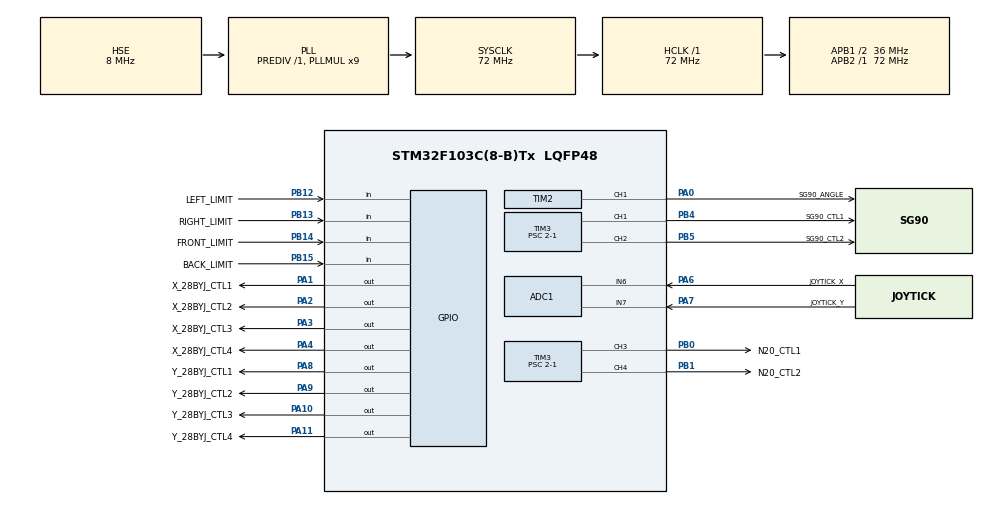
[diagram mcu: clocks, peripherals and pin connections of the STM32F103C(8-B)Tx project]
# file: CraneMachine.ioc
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ADC1.Channel-0\#ChannelRegularConversion=ADC_CHANNEL_6
ADC1.NbrOfConversionFlag=1
ADC1.Rank-0\#ChannelRegularConversion=1
ADC1.SamplingTime-0\#ChannelRegularConversion=ADC_SAMPLETIME_1CYCLE_5
ADC1.master=1
Mcu.Family=STM32F1
Mcu.Name=STM32F103C(8-B)Tx
Mcu.Package=LQFP48
NVIC.PriorityGroup=NVIC_PRIORITYGROUP_4
NVIC.TIM1_UP_IRQn=true\:0\:0\:false\:false\:true\:true\:true\:true
NVIC.TIM4_IRQn=true\:0\:0\:false\:false\:true\:true\:true\:true
PA0-WKUP.GPIO_Label=SG90_ANGLE
PA0-WKUP.GPIO_Speed=GPIO_SPEED_FREQ_HIGH
PA0-WKUP.Signal=S_TIM2_CH1_ETR
PA1.GPIO_Label=X_28BYJ_CTL1
PA1.GPIO_Speed=GPIO_SPEED_FREQ_HIGH
PA1.Signal=GPIO_Output
PA10.GPIO_Label=Y_28BYJ_CTL3
PA10.GPIO_Speed=GPIO_SPEED_FREQ_HIGH
PA10.Signal=GPIO_Output
PA11.GPIO_Label=Y_28BYJ_CTL4
PA11.GPIO_Speed=GPIO_SPEED_FREQ_HIGH
PA11.Signal=GPIO_Output
PA13.Mode=Serial_Wire
PA13.Signal=SYS_JTMS-SWDIO
PA14.Mode=Serial_Wire
PA14.Signal=SYS_JTCK-SWCLK
PA2.GPIO_Label=X_28BYJ_CTL2
PA2.GPIO_Speed=GPIO_SPEED_FREQ_HIGH
PA2.Signal=GPIO_Output
PA3.GPIO_Label=X_28BYJ_CTL3
PA3.GPIO_Speed=GPIO_SPEED_FREQ_HIGH
PA3.Signal=GPIO_Output
PA4.GPIO_Label=X_28BYJ_CTL4
PA4.GPIO_Speed=GPIO_SPEED_FREQ_HIGH
PA4.Signal=GPIO_Output
PA6.GPIO_Label=JOYTICK_X
PA6.Signal=ADCx_IN6
PA7.GPIO_Label=JOYTICK_Y
PA7.Signal=ADCx_IN7
PA8.GPIO_Label=Y_28BYJ_CTL1
PA8.GPIO_Speed=GPIO_SPEED_FREQ_HIGH
PA8.Signal=GPIO_Output
PA9.GPIO_Label=Y_28BYJ_CTL2
PA9.GPIO_Speed=GPIO_SPEED_FREQ_HIGH
PA9.Signal=GPIO_Output
PB0.GPIO_Label=N20_CTL1
PB0.GPIO_Speed=GPIO_SPEED_FREQ_HIGH
PB0.Signal=S_TIM3_CH3
PB1.GPIO_Label=N20_CTL2
PB1.Signal=S_TIM3_CH4
PB12.GPIO_Label=LEFT_LIMIT
PB12.GPIO_PuPd=GPIO_PULLUP
PB12.Signal=GPIO_Input
PB13.GPIO_Label=RIGHT_LIMIT
PB13.GPIO_PuPd=GPIO_PULLUP
PB13.Signal=GPIO_Input
PB14.GPIO_Label=FRONT_LIMIT
PB14.GPIO_PuPd=GPIO_PULLUP
PB14.Signal=GPIO_Input
PB15.GPIO_Label=BACK_LIMIT
PB15.GPIO_PuPd=GPIO_PULLUP
PB15.Signal=GPIO_Input
PB4.GPIO_Label=SG90_CTL1
PB4.GPIO_Speed=GPIO_SPEED_FREQ_HIGH
PB4.Signal=S_TIM3_CH1
PB5.GPIO_Label=SG90_CTL2
PB5.GPIO_Speed=GPIO_SPEED_FREQ_HIGH
PB5.Signal=S_TIM3_CH2
PD0-OSC_IN.Mode=HSE-External-Oscillator
PD0-OSC_IN.Signal=RCC_OSC_IN
PD1-OSC_OUT.Mode=HSE-External-Oscillator
PD1-OSC_OUT.Signal=RCC_OSC_OUT
ProjectManager.HeapSize=0x200
ProjectManager.StackSize=0x400
ProjectManager.TargetToolchain=MDK-ARM V5.32
RCC.ADCPresc=RCC_ADCPCLK2_DIV6
RCC.AHBFreq_Value=72000000
RCC.APB1CLKDivider=RCC_HCLK_DIV2
RCC.APB1Freq_Value=36000000
RCC.APB1TimFreq_Value=72000000
RCC.APB2Freq_Value=72000000
RCC.APB2TimFreq_Value=72000000
RCC.HCLKFreq_Value=72000000
RCC.PLLMUL=RCC_PLL_MUL9
RCC.PLLSourceVirtual=RCC_PLLSOURCE_HSE
RCC.SYSCLKFreq_VALUE=72000000
RCC.SYSCLKSource=RCC_SYSCLKSOURCE_PLLCLK
RCC.USBFreq_Value=72000000
SH.ADCx_IN6.0=ADC1_IN6,IN6
SH.ADCx_IN7.0=ADC1_IN7,IN7
SH.S_TIM2_CH1_ETR.0=TIM2_CH1,PWM Generation1 CH1
SH.S_TIM3_CH1.0=TIM3_CH1,PWM Generation1 CH1
SH.S_TIM3_CH2.0=TIM3_CH2,PWM Generation2 CH2
SH.S_TIM3_CH3.0=TIM3_CH3,PWM Generation3 CH3
SH.S_TIM3_CH4.0=TIM3_CH4,PWM Generation4 CH4
TIM1.AutoReloadPreload=TIM_AUTORELOAD_PRELOAD_ENABLE
TIM1.Period=1000-1
TIM1.Prescaler=72-1
TIM1.TIM_MasterOutputTrigger=TIM_TRGO_UPDATE
TIM2.AutoReloadPreload=TIM_AUTORELOAD_PRELOAD_ENABLE
TIM2.Channel-PWM\ Generation1\ CH1=TIM_CHANNEL_1
TIM2.Period=20000-1
TIM2.Prescaler=72-1
TIM3.AutoReloadPreload=TIM_AUTORELOAD_PRELOAD_ENABLE
TIM3.Channel-PWM\ Generation1\ CH1=TIM_CHANNEL_1
TIM3.Channel-PWM\ Generation2\ CH2=TIM_CHANNEL_2
TIM3.Channel-PWM\ Generation3\ CH3=TIM_CHANNEL_3
TIM3.Channel-PWM\ Generation4\ CH4=TIM_CHANNEL_4
TIM3.Period=1000-1
TIM3.Prescaler=2-1
TIM4.AutoReloadPreload=TIM_AUTORELOAD_PRELOAD_ENABLE
TIM4.Period=65535
TIM4.Prescaler=72-1
TIM4.TIM_MasterOutputTrigger=TIM_TRGO_UPDATE
VP_TIM1_VS_ClockSourceINT.Mode=Internal
VP_TIM2_VS_ClockSourceINT.Mode=Internal
VP_TIM3_VS_ClockSourceINT.Mode=Internal
VP_TIM4_VS_ClockSourceINT.Mode=Internal
board=custom

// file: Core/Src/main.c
/* USER CODE BEGIN Header */
/**
  ******************************************************************************
  * @file           : main.c
  * @brief          : Main program body
  ******************************************************************************
  * @attention
  *
  * Copyright (c) 2026 STMicroelectronics.
  * All rights reserved.
  *
  * This software is licensed under terms that can be found in the LICENSE file
  * in the root directory of this software component.
  * If no LICENSE file comes with this software, it is provided AS-IS.
  *
  ******************************************************************************
  */
/* USER CODE END Header */
#include "main.h"
#include "adc.h"
#include "tim.h"
#include "gpio.h"

/* USER CODE BEGIN Includes */
#include "cross.h"
#include "claw.h"
/* USER CODE END Includes */

void SystemClock_Config(void);

int main(void)
{

  /* MCU Configuration--------------------------------------------------------*/

  /* Reset of all peripherals, Initializes the Flash interface and the Systick. */
  HAL_Init();

  /* Configure the system clock */
  SystemClock_Config();

  /* Initialize all configured peripherals */
  MX_GPIO_Init();
  MX_TIM2_Init();
  MX_ADC1_Init();
  MX_TIM3_Init();
  MX_TIM4_Init();
  MX_TIM1_Init();
  /* USER CODE BEGIN 2 */
  Cross_Init(); // 初始化十字驱动模块
  Claw_Init();  // 初始化钩爪舵机模块
  /* USER CODE END 2 */

  /* Infinite loop */
  while (1)
  {

  }
}

void SystemClock_Config(void)
{
  RCC_OscInitTypeDef RCC_OscInitStruct = {0};
  RCC_ClkInitTypeDef RCC_ClkInitStruct = {0};
  RCC_PeriphCLKInitTypeDef PeriphClkInit = {0};

  /** Initializes the RCC Oscillators according to the specified parameters
  * in the RCC_OscInitTypeDef structure.
  */
  RCC_OscInitStruct.OscillatorType = RCC_OSCILLATORTYPE_HSE;
  RCC_OscInitStruct.HSEState = RCC_HSE_ON;
  RCC_OscInitStruct.HSEPredivValue = RCC_HSE_PREDIV_DIV1;
  RCC_OscInitStruct.HSIState = RCC_HSI_ON;
  RCC_OscInitStruct.PLL.PLLState = RCC_PLL_ON;
  RCC_OscInitStruct.PLL.PLLSource = RCC_PLLSOURCE_HSE;
  RCC_OscInitStruct.PLL.PLLMUL = RCC_PLL_MUL9;
  if (HAL_RCC_OscConfig(&RCC_OscInitStruct) != HAL_OK)
  {
    Error_Handler();
  }

  /** Initializes the CPU, AHB and APB buses clocks
  */
  RCC_ClkInitStruct.ClockType = RCC_CLOCKTYPE_HCLK|RCC_CLOCKTYPE_SYSCLK
                              |RCC_CLOCKTYPE_PCLK1|RCC_CLOCKTYPE_PCLK2;
  RCC_ClkInitStruct.SYSCLKSource = RCC_SYSCLKSOURCE_PLLCLK;
  RCC_ClkInitStruct.AHBCLKDivider = RCC_SYSCLK_DIV1;
  RCC_ClkInitStruct.APB1CLKDivider = RCC_HCLK_DIV2;
  RCC_ClkInitStruct.APB2CLKDivider = RCC_HCLK_DIV1;

  if (HAL_RCC_ClockConfig(&RCC_ClkInitStruct, FLASH_LATENCY_2) != HAL_OK)
  {
    Error_Handler();
  }
  PeriphClkInit.PeriphClockSelection = RCC_PERIPHCLK_ADC;
  PeriphClkInit.AdcClockSelection = RCC_ADCPCLK2_DIV6;
  if (HAL_RCCEx_PeriphCLKConfig(&PeriphClkInit) != HAL_OK)
  {
    Error_Handler();
  }
}

void Error_Handler(void)
{
  __disable_irq();
  while (1)
  {
  }
}
